# B6x register map
Vendor: XiaoMan; Series: B6 SOC; File version: 20260307
CPU: CM0+ r0p0, little endian, no MPU, no FPU, 2 interrupt priority bits
Registers are 32-bit, read-write, reset 0x0 unless marked. A register's access mark holds for its fields unless they carry their own. Offsets are from the block's base; [hi:lo] are bit positions; {n}, {i} and the like mark numbered series; 'fields as' and 'values as' point back to an identical list.

## ATMR — Advanced Timer
Base 0x40022000
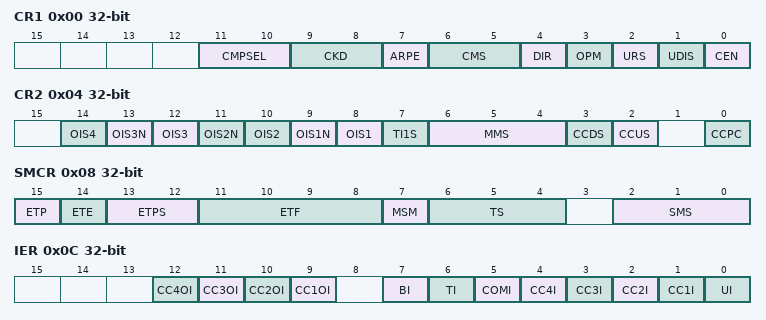
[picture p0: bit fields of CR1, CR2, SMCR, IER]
0x00 CR1 — Control register 1
  [11:10] CMPSEL — Compare input Select (Only ATMR)
  [9:8] CKD — Clock Division
  [7] ARPE — Auto-Reload Preload Enable
  [6:5] CMS — Center-aligned Mode Select
  [4] DIR — Direction
  [3] OPM — One Pulse Mode
  [2] URS — Update Request Source
  [1] UDIS — Update Disable
  [0] CEN — Counter Enable
0x04 CR2 — Control register 2
  [2n+6] OIS{n} (n=1..4) — Output Idle State{n} (OC{n} Output) (Only ATMR)
  [13] OIS3N — Output Idle State3 (OC3N Output) (Only ATMR)
  [11] OIS2N — Output Idle State2 (OC2N Output) (Only ATMR)
  [9] OIS1N — Output Idle State1 (OC1N Output) (Only ATMR)
  [7] TI1S — TI1 Select
  [6:4] MMS — Master Mode Select
  [3] CCDS — Capture/Compare DMA Select
  [2] CCUS — Capture/Compare Control Update Select (Only ATMR)
  [0] CCPC — Capture/Compare Preload Control (Only ATMR)
0x08 SMCR — Slave mode control register
  [15] ETP — External Trigger Polarity
  [14] ETE — External Clock Enable
  [13:12] ETPS — External Trigger Prescaler
  [11:8] ETF — External Trigger Filter
  [7] MSM — Master/Slave Mode
  [6:4] TS — Trigger Select
  [2:0] SMS — Slave Mode Select
    0=Disabled (Slave mode disabled); 4=Reset_Mode (Rising edge of TRGI reinitializes counter); 5=Gated_Mode (Counter clock enabled when TRGI is high); 6=Trigger_Mode (Counter starts at rising edge of TRGI)
0x0C IER wo — Interrupt Enable register
  [n+8] CC{n}OI (n=1..4) — Capture/Compare {n} Overcapture Interrupt
  [7] BI — Break Interrupt (Only ATMR)
  [6] TI — Trigger Interrupt
  [5] COMI — COM Interrupt (Only ATMR)
  [n] CC{n}I (n=1..4) — Capture/Compare {n} Interrupt
  [0] UI — Update Interrupt
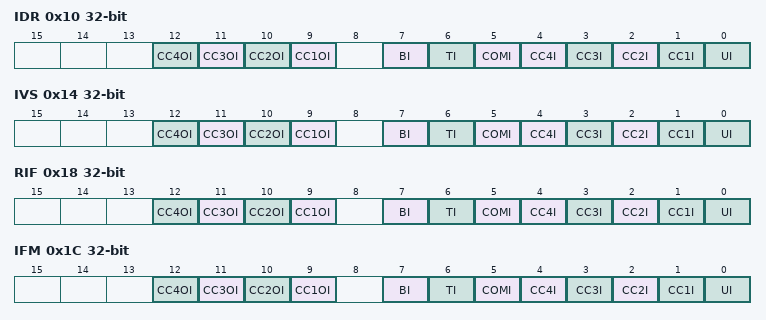
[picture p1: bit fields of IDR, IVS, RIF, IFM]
0x10 IDR wo — Interrupt Disable register
  fields as IER
0x14 IVS ro — Interrupt Valid status register
  [n+8] CC{n}OI (n=1..4) — Capture/Compare {n} Overcapture Interrupt Valid Status
  [7] BI — Break Interrupt Valid Status (Only ATMR)
  [6] TI — Trigger Interrupt Valid Status
  [5] COMI — COM Interrupt Valid Status (Only ATMR)
  [n] CC{n}I (n=1..4) — Capture/Compare {n} Interrupt Valid Status
  [0] UI — Update Interrupt Valid Status
0x18 RIF ro — Raw interrupt Flag
  [n+8] CC{n}OI (n=1..4) — Capture/Compare {n} Overcapture Raw Interrupt Flag
  [7] BI — Break Raw Interrupt Flag (Only ATMR)
  [6] TI — Trigger Raw Interrupt Flag
  [5] COMI — COM Raw Interrupt Flag (Only ATMR)
  [n] CC{n}I (n=1..4) — Capture/Compare {n} Raw Interrupt Flag
  [0] UI — Update Raw Interrupt Flag
0x1C IFM ro — Masked interrupt Flag
  [n+8] CC{n}OI (n=1..4) — Capture/Compare {n} Overcapture Masked Interrupt Flag
  [7] BI — Break Masked Interrupt Flag (Only ATMR)
  [6] TI — Trigger Masked Interrupt Flag
  [5] COMI — COM Masked Interrupt Flag (Only ATMR)
  [n] CC{n}I (n=1..4) — Capture/Compare {n} Masked Interrupt Flag
  [0] UI — Update Masked Interrupt Flag
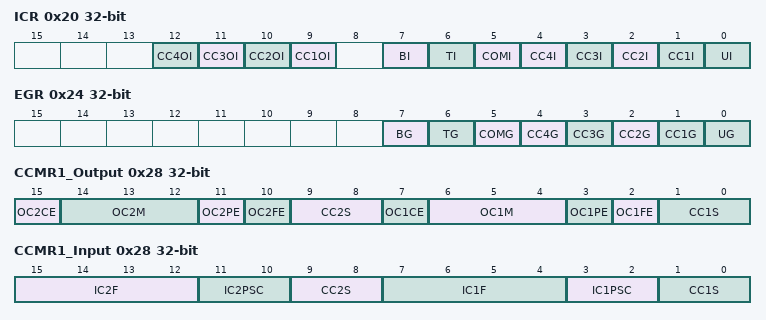
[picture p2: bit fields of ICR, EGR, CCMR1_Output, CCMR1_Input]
0x20 ICR wo — Interrupt Clear status register
  [n+8] CC{n}OI (n=1..4) — Capture/Compare {n} Overcapture Interrupt Clear
  [7] BI — Break Interrupt Clear (Only ATMR)
  [6] TI — Trigger Interrupt Clear
  [5] COMI — COM Interrupt Clear (Only ATMR)
  [n] CC{n}I (n=1..4) — Capture/Compare {n} Interrupt Clear
  [0] UI — Update Interrupt Clear
0x24 EGR — Event generation register
  [7] BG — Break Generation (Only ATMR)
  [6] TG — Trigger Generation
  [5] COMG — Capture/Compare Control Update Generation (Only ATMR)
  [n] CC{n}G (n=1..4) — Capture/Compare {n} Generation
  [0] UG — Update Generation
0x28 CCMR1_Output — Capture/compare mode register 1 (Output mode)
  [15] OC2CE — Output Compare 2 Clear Enable
  [14:12] OC2M — Output Compare 2 Mode
  [11] OC2PE — Output Compare 2 Preload Enable
  [10] OC2FE — Output Compare 2 Fast Enable
  [9:8] CC2S — Capture/Compare 2 Select
  [7] OC1CE — Output Compare 1 Clear Enable
  [6:4] OC1M — Output Compare 1 Mode
    0=Frozen; 1=Active_on_match (Set channel to active level on match); 2=Inactive_on_match (Set channel to inactive level on match); 3=Toggle; 4=Force inactive level; 5=Force active level; 6=PWM_mode1; 7=PWM_mode2
  [3] OC1PE — Output Compare 1 Preload Enable
  [2] OC1FE — Output Compare 1 Fast Enable
  [1:0] CC1S — Capture/Compare 1 Select
0x28 CCMR1_Input (alternate view of CCMR1_Output) — Capture/compare mode register 1 (Input mode)
  [15:12] IC2F — Input Capture 2 Filter
  [11:10] IC2PSC — Input Capture 2 Prescaler
  [9:8] CC2S — Capture/Compare 2 Select
  [7:4] IC1F — Input Capture 1 Filter
  [3:2] IC1PSC — Input Capture 1 Prescaler
  [1:0] CC1S — Capture/Compare 1 Select
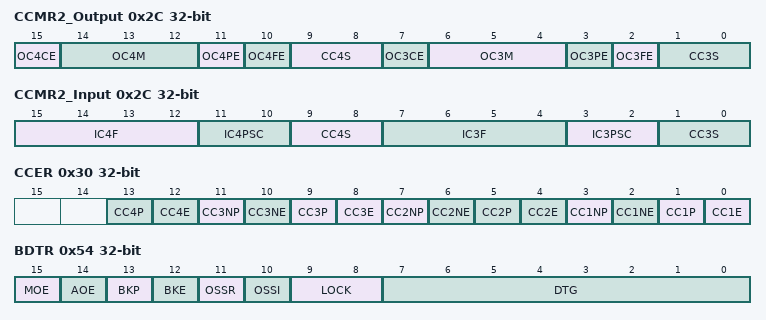
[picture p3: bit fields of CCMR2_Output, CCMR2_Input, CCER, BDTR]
0x2C CCMR2_Output — Capture/compare mode register 2 (Output mode)
  [15] OC4CE — Output Compare 4 Clear Enable
  [14:12] OC4M — Output Compare 4 Mode
  [11] OC4PE — Output Compare 4 Preload Enable
  [10] OC4FE — Output Compare 4 Fast Enable
  [9:8] CC4S — Capture/Compare 4 Select
  [7] OC3CE — Output Compare 3 Clear Enable
  [6:4] OC3M — Output Compare 3 Mode
  [3] OC3PE — Output Compare 3 Preload Enable
  [2] OC3FE — Output Compare 3 Fast Enable
  [1:0] CC3S — Capture/Compare 3 Select
0x2C CCMR2_Input (alternate view of CCMR2_Output) — Capture/compare mode register 2 (Input mode)
  [15:12] IC4F — Input Capture 4 Filter
  [11:10] IC4PSC — Input Capture 4 Prescaler
  [9:8] CC4S — Capture/Compare 4 Select
  [7:4] IC3F — Input Capture 3 Filter
  [3:2] IC3PSC — Input Capture 3 Prescaler
  [1:0] CC3S — Capture/Compare 3 Select
0x30 CCER — Capture/compare enable register
  [4n-3] CC{n}P (n=1..4) — Capture/Compare {n} Output Polarity
  [4n-4] CC{n}E (n=1..4) — Capture/Compare {n} Output Enable
  [11] CC3NP — Capture/Compare 3 Complementary Output Polarity (Only ATMR)
  [10] CC3NE — Capture/Compare 3 Complementary Output Enable (Only ATMR)
  [7] CC2NP — Capture/Compare 2 Complementary Output Polarity (Only ATMR)
  [6] CC2NE — Capture/Compare 2 Complementary Output Enable (Only ATMR)
  [3] CC1NP — Capture/Compare 1 Complementary Output Polarity (Only ATMR)
  [2] CC1NE — Capture/Compare 1 Complementary Output Enable (Only ATMR)
0x34 CNT — Timer Counter
0x38 PSC — Prescaler
0x3C ARR — Auto-reload register
0x40 RCR — Repetition counter register (Only ATMR)
{0x40+4i} CCR{i} (i=1..4) — Capture/compare register {i}
0x54 BDTR — Break and dead-time register (Only ATMR)
  [15] MOE — Main Output Enable
  [14] AOE — Automatic Output Enable
  [13] BKP — Break Polarity
  [12] BKE — Break Enable
  [11] OSSR — Off-state Selection for Run Mode
  [10] OSSI — Off-state Selection for Idle Mode
  [9:8] LOCK — Lock Configuration
    0=Level_0 (No lock); 1=Level_1 (Lock Level 1); 2=Level_2 (Lock Level 2); 3=Level_3 (Lock Level 3)
  [7:0] DTG — Dead-Time Generator Setup
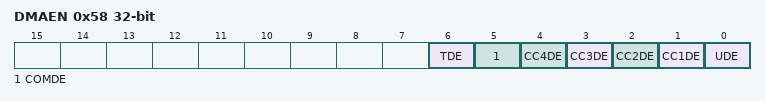
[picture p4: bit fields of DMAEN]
0x58 DMAEN — DMA trigger event enable
  [6] TDE — Trigger DMA Request Enable
  [5] COMDE — COM DMA Request Enable (Only ATMR)
  [n] CC{n}DE (n=1..4) — Capture/Compare {n} DMA Request Enable
  [0] UDE — Update DMA Request Enable
